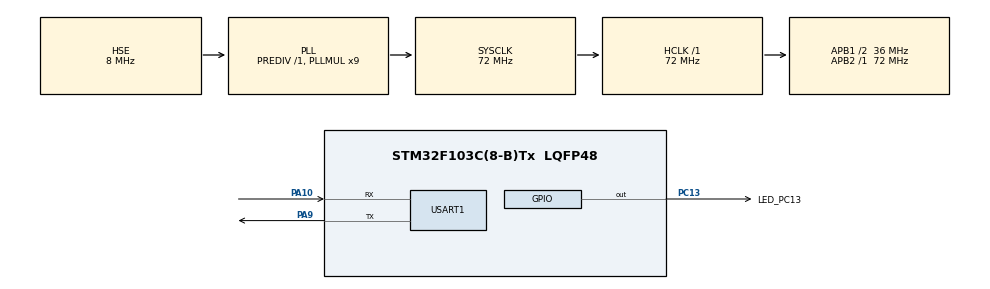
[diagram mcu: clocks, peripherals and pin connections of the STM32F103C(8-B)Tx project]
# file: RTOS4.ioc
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Dma.Request0=USART1_RX
Dma.Request1=USART1_TX
Dma.USART1_RX.0.Direction=DMA_PERIPH_TO_MEMORY
Dma.USART1_RX.0.Instance=DMA1_Channel5
Dma.USART1_RX.0.MemDataAlignment=DMA_MDATAALIGN_BYTE
Dma.USART1_RX.0.MemInc=DMA_MINC_ENABLE
Dma.USART1_RX.0.Mode=DMA_NORMAL
Dma.USART1_RX.0.PeriphDataAlignment=DMA_PDATAALIGN_BYTE
Dma.USART1_RX.0.PeriphInc=DMA_PINC_DISABLE
Dma.USART1_RX.0.Priority=DMA_PRIORITY_LOW
Dma.USART1_TX.1.Direction=DMA_MEMORY_TO_PERIPH
Dma.USART1_TX.1.Instance=DMA1_Channel4
Dma.USART1_TX.1.MemDataAlignment=DMA_MDATAALIGN_BYTE
Dma.USART1_TX.1.MemInc=DMA_MINC_ENABLE
Dma.USART1_TX.1.Mode=DMA_NORMAL
Dma.USART1_TX.1.PeriphDataAlignment=DMA_PDATAALIGN_BYTE
Dma.USART1_TX.1.PeriphInc=DMA_PINC_DISABLE
Dma.USART1_TX.1.Priority=DMA_PRIORITY_LOW
FREERTOS.BinarySemaphores01=myBinarySem01,Dynamic,NULL,Available
FREERTOS.Queues01=myQueue01,16,uint16_t,0,Dynamic,NULL,NULL
FREERTOS.Tasks01=defaultTask,0,128,StartDefaultTask,Default,NULL,Dynamic,NULL,NULL;LEDTask,-2,128,ledcontrolFun,Default,NULL,Dynamic,NULL,NULL;USBFTask,-2,128,UARTCONTROLFun,Default,NULL,Dynamic,NULL,NULL
Mcu.Family=STM32F1
Mcu.Name=STM32F103C(8-B)Tx
Mcu.Package=LQFP48
NVIC.DMA1_Channel4_IRQn=true\:5\:0\:false\:false\:true\:true\:false\:true\:true
NVIC.DMA1_Channel5_IRQn=true\:5\:0\:false\:false\:true\:true\:false\:true\:true
NVIC.PriorityGroup=NVIC_PRIORITYGROUP_4
NVIC.TIM4_IRQn=true\:15\:0\:false\:false\:true\:false\:false\:true\:true
NVIC.TimeBase=TIM4_IRQn
NVIC.TimeBaseIP=TIM4
NVIC.USART1_IRQn=true\:5\:0\:false\:false\:true\:true\:false\:true\:true
PA10.Mode=Asynchronous
PA10.Signal=USART1_RX
PA13.Mode=Serial_Wire
PA13.Signal=SYS_JTMS-SWDIO
PA14.Mode=Serial_Wire
PA14.Signal=SYS_JTCK-SWCLK
PA9.Mode=Asynchronous
PA9.Signal=USART1_TX
PC13-TAMPER-RTC.GPIO_Label=LED_PC13
PC13-TAMPER-RTC.GPIO_ModeDefaultOutputPP=GPIO_MODE_OUTPUT_OD
PC13-TAMPER-RTC.GPIO_PuPd=GPIO_PULLUP
PC13-TAMPER-RTC.Signal=GPIO_Output
PC14-OSC32_IN.Mode=LSE-External-Oscillator
PC14-OSC32_IN.Signal=RCC_OSC32_IN
PC15-OSC32_OUT.Mode=LSE-External-Oscillator
PC15-OSC32_OUT.Signal=RCC_OSC32_OUT
PD0-OSC_IN.Mode=HSE-External-Oscillator
PD0-OSC_IN.Signal=RCC_OSC_IN
PD1-OSC_OUT.Mode=HSE-External-Oscillator
PD1-OSC_OUT.Signal=RCC_OSC_OUT
ProjectManager.HeapSize=0x200
ProjectManager.StackSize=0x400
ProjectManager.TargetToolchain=CMake
RCC.AHBFreq_Value=72000000
RCC.APB1CLKDivider=RCC_HCLK_DIV2
RCC.APB1Freq_Value=36000000
RCC.APB1TimFreq_Value=72000000
RCC.APB2Freq_Value=72000000
RCC.APB2TimFreq_Value=72000000
RCC.HCLKFreq_Value=72000000
RCC.PLLMUL=RCC_PLL_MUL9
RCC.PLLSourceVirtual=RCC_PLLSOURCE_HSE
RCC.SYSCLKFreq_VALUE=72000000
RCC.SYSCLKSource=RCC_SYSCLKSOURCE_PLLCLK
RCC.USBFreq_Value=72000000
USART1.VirtualMode=VM_ASYNC
VP_FREERTOS_VS_CMSIS_V1.Mode=CMSIS_V1
VP_SYS_VS_tim4.Mode=TIM4
board=custom

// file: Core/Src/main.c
/* USER CODE BEGIN Header */
/**
  ******************************************************************************
  * @file           : main.c
  * @brief          : Main program body
  ******************************************************************************
  * @attention
  *
  * Copyright (c) 2025 STMicroelectronics.
  * All rights reserved.
  *
  * This software is licensed under terms that can be found in the LICENSE file
  * in the root directory of this software component.
  * If no LICENSE file comes with this software, it is provided AS-IS.
  *
  ******************************************************************************
  */
/* USER CODE END Header */
#include "main.h"
#include "cmsis_os.h"
#include "dma.h"
#include "usart.h"
#include "gpio.h"

/* USER CODE BEGIN Includes */
#include <string.h>
#include "stm32f1xx_hal_uart.h"
extern uint8_t buf[128];
extern int uart_flag;
/* USER CODE END Includes */

void SystemClock_Config(void);
void MX_FREERTOS_Init(void);
void UART_Receive(void);

int main(void)
{

  /* MCU Configuration--------------------------------------------------------*/

  /* Reset of all peripherals, Initializes the Flash interface and the Systick. */
  HAL_Init();

  /* Configure the system clock */
  SystemClock_Config();

  /* Initialize all configured peripherals */
  MX_GPIO_Init();
  MX_DMA_Init();
  MX_USART1_UART_Init();
  /* USER CODE BEGIN 2 */
  memset(buf, 0, 128);
  HAL_UART_Receive_DMA(&huart1, buf, 128);
  __HAL_UART_ENABLE_IT(&huart1, UART_IT_IDLE);
  /* USER CODE END 2 */

  /* Call init function for freertos objects (in cmsis_os2.c) */
  MX_FREERTOS_Init();

  /* Start scheduler */
  osKernelStart();

  /* We should never get here as control is now taken by the scheduler */

  /* Infinite loop */
  while (1)
  {

  }
}

void SystemClock_Config(void)
{
  RCC_OscInitTypeDef RCC_OscInitStruct = {0};
  RCC_ClkInitTypeDef RCC_ClkInitStruct = {0};

  /** Initializes the RCC Oscillators according to the specified parameters
  * in the RCC_OscInitTypeDef structure.
  */
  RCC_OscInitStruct.OscillatorType = RCC_OSCILLATORTYPE_HSE;
  RCC_OscInitStruct.HSEState = RCC_HSE_ON;
  RCC_OscInitStruct.HSEPredivValue = RCC_HSE_PREDIV_DIV1;
  RCC_OscInitStruct.HSIState = RCC_HSI_ON;
  RCC_OscInitStruct.PLL.PLLState = RCC_PLL_ON;
  RCC_OscInitStruct.PLL.PLLSource = RCC_PLLSOURCE_HSE;
  RCC_OscInitStruct.PLL.PLLMUL = RCC_PLL_MUL9;
  if (HAL_RCC_OscConfig(&RCC_OscInitStruct) != HAL_OK)
  {
    Error_Handler();
  }

  /** Initializes the CPU, AHB and APB buses clocks
  */
  RCC_ClkInitStruct.ClockType = RCC_CLOCKTYPE_HCLK|RCC_CLOCKTYPE_SYSCLK
                              |RCC_CLOCKTYPE_PCLK1|RCC_CLOCKTYPE_PCLK2;
  RCC_ClkInitStruct.SYSCLKSource = RCC_SYSCLKSOURCE_PLLCLK;
  RCC_ClkInitStruct.AHBCLKDivider = RCC_SYSCLK_DIV1;
  RCC_ClkInitStruct.APB1CLKDivider = RCC_HCLK_DIV2;
  RCC_ClkInitStruct.APB2CLKDivider = RCC_HCLK_DIV1;

  if (HAL_RCC_ClockConfig(&RCC_ClkInitStruct, FLASH_LATENCY_2) != HAL_OK)
  {
    Error_Handler();
  }
}

void HAL_TIM_PeriodElapsedCallback(TIM_HandleTypeDef *htim)
{
  if (htim->Instance == TIM4)
  {
    HAL_IncTick();
  }
}

void Error_Handler(void)
{
  __disable_irq();
  while (1)
  {
  }
}

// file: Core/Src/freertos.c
/* USER CODE BEGIN Header */
/**
  ******************************************************************************
  * File Name          : freertos.c
  * Description        : Code for freertos applications
  ******************************************************************************
  * @attention
  *
  * Copyright (c) 2025 STMicroelectronics.
  * All rights reserved.
  *
  * This software is licensed under terms that can be found in the LICENSE file
  * in the root directory of this software component.
  * If no LICENSE file comes with this software, it is provided AS-IS.
  *
  ******************************************************************************
  */
/* USER CODE END Header */

#include "FreeRTOS.h"
#include "task.h"
#include "main.h"
#include "cmsis_os.h"

/* USER CODE BEGIN Includes */
#include "stm32f1xx_hal_uart.h"
#include <stdint.h>
#include <ctype.h>
#include <string.h>
/* USER CODE END Includes */

/* USER CODE BEGIN Variables */
extern UART_HandleTypeDef huart1;
QueueHandle_t messageQueue1;
uint8_t buf[128];
volatile uint8_t uart_flag = 0;
volatile uint16_t uart_len = 0;
uint16_t buffer = 500;
uint16_t millisec = 500;
/* USER CODE END Variables */
osThreadId defaultTaskHandle;
osThreadId LEDTaskHandle;
osThreadId USBFTaskHandle;
osMessageQId myQueue01Handle;
osSemaphoreId myBinarySem01Handle;

/* USER CODE BEGIN FunctionPrototypes */
void UART_Process_Data(void);
void UART_Reset_Buffer(void);
/* USER CODE END FunctionPrototypes */

void StartDefaultTask(void const * argument);
void ledcontrolFun(void const * argument);
void UARTCONTROLFun(void const * argument);

void MX_FREERTOS_Init(void); /* (MISRA C 2004 rule 8.1) */

/* GetIdleTaskMemory prototype (linked to static allocation support) */
void vApplicationGetIdleTaskMemory( StaticTask_t **ppxIdleTaskTCBBuffer, StackType_t **ppxIdleTaskStackBuffer, uint32_t *pulIdleTaskStackSize );

/* USER CODE BEGIN GET_IDLE_TASK_MEMORY */
static StaticTask_t xIdleTaskTCBBuffer;
static StackType_t xIdleStack[configMINIMAL_STACK_SIZE];

void vApplicationGetIdleTaskMemory( StaticTask_t **ppxIdleTaskTCBBuffer, StackType_t **ppxIdleTaskStackBuffer, uint32_t *pulIdleTaskStackSize )
{
  *ppxIdleTaskTCBBuffer = &xIdleTaskTCBBuffer;
  *ppxIdleTaskStackBuffer = &xIdleStack[0];
  *pulIdleTaskStackSize = configMINIMAL_STACK_SIZE;
  /* place for user code */
}
/* USER CODE END GET_IDLE_TASK_MEMORY */

void MX_FREERTOS_Init(void) {

  /* Create the semaphores(s) */
  /* definition and creation of myBinarySem01 */
  osSemaphoreDef(myBinarySem01);
  myBinarySem01Handle = osSemaphoreCreate(osSemaphore(myBinarySem01), 1);

  /* Create the queue(s) */
  /* definition and creation of myQueue01 */
  osMessageQDef(myQueue01, 16, uint16_t);
  myQueue01Handle = osMessageCreate(osMessageQ(myQueue01), NULL);

  /* USER CODE BEGIN RTOS_QUEUES */
  /* add queues, ... */
    messageQueue1 = xQueueCreate(10, sizeof(uint16_t)); // 创建大小为10的消息队列

  /* USER CODE END RTOS_QUEUES */

  /* Create the thread(s) */
  /* definition and creation of defaultTask */
  osThreadDef(defaultTask, StartDefaultTask, osPriorityNormal, 0, 128);
  defaultTaskHandle = osThreadCreate(osThread(defaultTask), NULL);

  /* definition and creation of LEDTask */
  osThreadDef(LEDTask, ledcontrolFun, osPriorityLow, 0, 128);
  LEDTaskHandle = osThreadCreate(osThread(LEDTask), NULL);

  /* definition and creation of USBFTask */
  osThreadDef(USBFTask, UARTCONTROLFun, osPriorityLow, 0, 128);
  USBFTaskHandle = osThreadCreate(osThread(USBFTask), NULL);

  /* USER CODE BEGIN RTOS_THREADS */
  /* add threads, ... */
   vTaskStartScheduler();
  /* USER CODE END RTOS_THREADS */

}

void StartDefaultTask(void const * argument)
{
  for(;;)
  {
    osDelay(1);
  }
}

void ledcontrolFun(void const * argument)
{
  /* USER CODE BEGIN ledcontrolFun */
  /* Infinite loop */
  for(;;)
  {
    uint16_t data;

    // 从消息队列接收数据
    if(xQueueReceive(messageQueue1, &data, pdMS_TO_TICKS(10)) == pdPASS){
      if(data >= 100 && data <= 1500){
        millisec = data;  // 更新LED闪烁间隔
      }
    };

    // 控制LED闪烁
    HAL_GPIO_TogglePin(LED_PC13_GPIO_Port, LED_PC13_Pin);
    osDelay(millisec);
  }
  /* USER CODE END ledcontrolFun */
}

void UARTCONTROLFun(void const * argument)
{
  /* USER CODE BEGIN UARTCONTROLFun */
  /* Infinite loop */
  for(;;)
  {
    // 如果有新的UART数据到达
    if(uart_flag == 1){
      UART_Process_Data();   // 处理UART数据
      UART_Reset_Buffer();   // 重置UART缓冲区
    }
    osDelay(10);  // 10ms延时，避免任务占用过多CPU
  }
  /* USER CODE END UARTCONTROLFun */
}

/* USER CODE BEGIN 4 */
/**
  * @brief  UART数据处理函数
  * @retval None
  */
void UART_Process_Data(void)
{
  if(uart_flag == 0) {
    return;  // 没有新数据，直接返回
  }

  uint16_t result = 0;

  // 解析接收到的数字
  for(int i = 0; i < uart_len; i++){
    if(isdigit(buf[i])){
      result = result * 10 + (buf[i] - '0');
    }
    else if(buf[i] == '\n' || buf[i] == '\r' || buf[i] == 0){
      break;  // 遇到结束符就停止解析
    }
  }

  // 如果解析到有效数据，发送到消息队列
  if (result > 0){
    buffer = result;
    xQueueSend(messageQueue1, &buffer, 0);
  }
}

/**
  * @brief  UART缓冲区重置函数
  * @retval None
  */
void UART_Reset_Buffer(void)
{
  // 重置标志和长度
  uart_flag = 0;
  uart_len = 0;

  // 清空缓冲区
  memset(buf, 0, 128);

  // 重新启动DMA接收，准备接收下一批数据
  HAL_UART_Receive_DMA(&huart1, buf, 128);
}
/* USER CODE END 4 */
